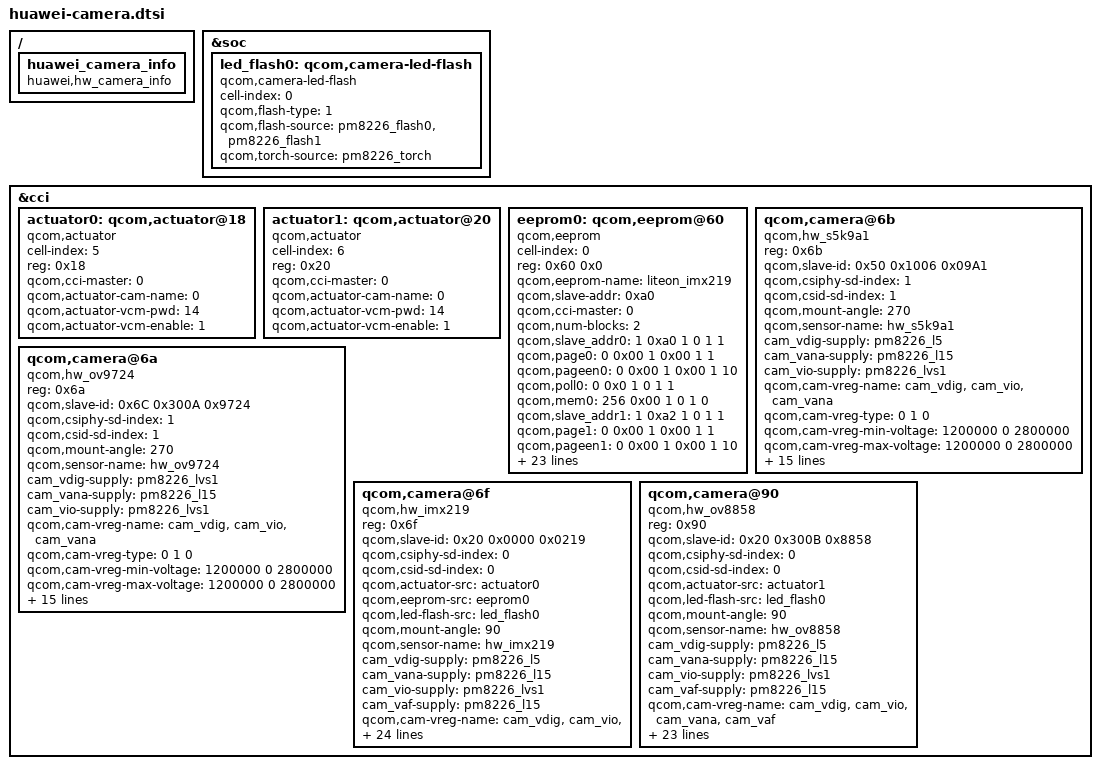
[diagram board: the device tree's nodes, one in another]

 / {
        huawei_camera_info {
                  compatible = "huawei,hw_camera_info";
                  status = "ok";
        };
};

&soc {

	led_flash0: qcom,camera-led-flash {
		cell-index = <0>;
		compatible = "qcom,camera-led-flash";
		qcom,flash-type = <1>;
		qcom,flash-source = <&pm8226_flash0 &pm8226_flash1>;
		qcom,torch-source = <&pm8226_torch>;
	};
};

&cci {
	actuator0: qcom,actuator@18 {
		cell-index = <5>;
		reg = <0x18>;
		compatible = "qcom,actuator";
		qcom,cci-master = <0>;
		qcom,actuator-cam-name = <0>;
		qcom,actuator-vcm-pwd = <14>;
		qcom,actuator-vcm-enable = <1>;
	};
	actuator1: qcom,actuator@20 {
		cell-index = <6>;
		reg = <0x20>;
		compatible = "qcom,actuator";
		qcom,cci-master = <0>;
		qcom,actuator-cam-name = <0>;
		qcom,actuator-vcm-pwd = <14>;
		qcom,actuator-vcm-enable = <1>;
	};
	
	eeprom0: qcom,eeprom@60 {
		cell-index = <0>;
		reg = <0x60 0x0>; //a fake addr for register, mclk src already defined 6-0060.
		qcom,eeprom-name = "liteon_imx219";
		compatible = "qcom,eeprom";
		qcom,slave-addr = <0xa0>;
		qcom,cci-master = <0>;
		qcom,num-blocks = <2>;
		qcom,slave_addr0 = <1 0xa0 1 0 1 1>;
		qcom,page0 = <0 0x00 1 0x00 1 1>;
		qcom,pageen0 = <0 0x00 1 0x00 1 10>;
		qcom,poll0 = <0 0x0 1 0 1 1>;
		qcom,mem0 = <256 0x00 1 0 1 0>;

		qcom,slave_addr1 = <1 0xa2 1 0 1 1>;
		qcom,page1 = <0 0x00 1 0x00 1 1>;
		qcom,pageen1 = <0 0x00 1 0x00 1 10>;
		qcom,poll1 = <0 0x0 1 0 1 1>;
		qcom,mem1 = <40 0x00 1 0 1 0>;

		cam_vdig-supply = <&pm8226_l5>;
		cam_vio-supply = <&pm8226_lvs1>;
		cam_vana-supply = <&pm8226_l15>;
		qcom,cam-vreg-name = "cam_vdig", "cam_vio", "cam_vana";
		qcom,cam-vreg-type = <0 1 0>;
		qcom,cam-vreg-min-voltage = <1200000 0 2800000>;
		qcom,cam-vreg-max-voltage = <1200000 0 2800000>;
		qcom,cam-vreg-op-mode = <200000 0 80000>;
		qcom,gpio-no-mux = <0>;
		gpios = <&msmgpio 26 0>,
			<&msmgpio 37 0>;//reset
		qcom,gpio-reset = <1>;
		qcom,gpio-req-tbl-num = <0 1>;
		qcom,gpio-req-tbl-flags = <1 0>;
		qcom,gpio-req-tbl-label = "CAMIF_MCLK",
				"CAM_RESET";
		qcom,cam-power-seq-type = "sensor_vreg",
				"sensor_vreg", "sensor_gpio",
				"sensor_clk";
		qcom,cam-power-seq-val = "cam_vio", "cam_vana",
				"sensor_gpio_reset",
				"sensor_cam_mclk" ;
		qcom,cam-power-seq-cfg-val = <1 1 1 24000000>;
		qcom,cam-power-seq-delay = <1 1 10 5>;
	};
	
	qcom,camera@6b {
		compatible = "qcom,hw_s5k9a1";
		reg = <0x6b>;
		qcom,slave-id = <0x50 0x1006 0x09A1>;
		qcom,csiphy-sd-index = <1>;
		qcom,csid-sd-index = <1>;
		qcom,mount-angle = <270>;
		qcom,sensor-name = "hw_s5k9a1";
		cam_vdig-supply = <&pm8226_l5>;
		cam_vana-supply = <&pm8226_l15>;
		cam_vio-supply = <&pm8226_lvs1>;
		qcom,cam-vreg-name = "cam_vdig", "cam_vio", "cam_vana";
		qcom,cam-vreg-type = <0 1 0>;
		qcom,cam-vreg-min-voltage = <1200000 0 2800000>;
		qcom,cam-vreg-max-voltage = <1200000 0 2800000>;
		qcom,cam-vreg-op-mode = <200000 0 80000>;
		qcom,gpio-no-mux = <0>;
		gpios = <&msmgpio 26 0>,
				<&msmgpio 28 0>;
		qcom,gpio-reset = <1>;
		qcom,gpio-req-tbl-num = <0 1>;
		qcom,gpio-req-tbl-flags = <1 0>;
		qcom,gpio-req-tbl-label = "CAMIF_MCLK",
				"CAM_RESET";
		qcom,gpio-set-tbl-num = <0 1>;
		qcom,gpio-set-tbl-flags = <1 0>;
		qcom,gpio-set-tbl-delay = <1000 4000>;
		qcom,csi-lane-assign = <0x4320>;
		qcom,csi-lane-mask = <0x3>;
		qcom,sensor-position = <1>;
		qcom,sensor-mode = <1>;
		qcom,cci-master = <0>;
		status = "ok";
	};
	qcom,camera@6a {
		compatible = "qcom,hw_ov9724";
		reg = <0x6a>;
		qcom,slave-id = <0x6C 0x300A 0x9724>;
		qcom,csiphy-sd-index = <1>;
		qcom,csid-sd-index = <1>;
		qcom,mount-angle = <270>;   /* not preset so far */
		qcom,sensor-name = "hw_ov9724";
		cam_vdig-supply = <&pm8226_lvs1>;
		cam_vana-supply = <&pm8226_l15>;
		cam_vio-supply = <&pm8226_lvs1>;
		qcom,cam-vreg-name = "cam_vdig", "cam_vio", "cam_vana";
		qcom,cam-vreg-type = <0 1 0>;
		qcom,cam-vreg-min-voltage = <1200000 0 2800000>;
		qcom,cam-vreg-max-voltage = <1200000 0 2800000>;
		qcom,cam-vreg-op-mode = <200000 0 80000>;
		qcom,gpio-no-mux = <0>;
		gpios = <&msmgpio 26 0>,
				<&msmgpio 28 0>;
		qcom,gpio-reset = <1>;
		qcom,gpio-req-tbl-num = <0 1>;
		qcom,gpio-req-tbl-flags = <1 0>;
		qcom,gpio-req-tbl-label = "CAMIF_MCLK",
				"CAM_RESET";
		qcom,gpio-set-tbl-num = <0 1>;
		qcom,gpio-set-tbl-flags = <1 0>;
		qcom,gpio-set-tbl-delay = <1000 4000>;
		qcom,csi-lane-assign = <0xE4>;
		qcom,csi-lane-mask = <0xF>;
		qcom,sensor-position = <1>;
		qcom,sensor-mode = <1>;
		qcom,cci-master = <0>;
		status = "ok";
	};
	qcom,camera@6f{
		compatible = "qcom,hw_imx219";
		reg = <0x6f>;
		qcom,slave-id = <0x20 0x0000 0x0219>;
		qcom,csiphy-sd-index = <0>;
		qcom,csid-sd-index = <0>;
		qcom,actuator-src = <&actuator0>;
		qcom,eeprom-src = <&eeprom0>;
		qcom,led-flash-src = <&led_flash0>;
		qcom,mount-angle = <90>;
		qcom,sensor-name = "hw_imx219";
		cam_vdig-supply = <&pm8226_l5>;
		cam_vana-supply = <&pm8226_l15>;
		cam_vio-supply = <&pm8226_lvs1>;
		cam_vaf-supply = <&pm8226_l15>;
		qcom,cam-vreg-name = "cam_vdig", "cam_vio",
					"cam_vana", "cam_vaf";
		qcom,cam-vreg-type = <0 1 0 0>;
		qcom,cam-vreg-min-voltage = <1200000 0 2800000 2800000>;
		qcom,cam-vreg-max-voltage = <1200000 0 2800000 2800000>;
		qcom,cam-vreg-op-mode = <200000 0 80000 100000>;
		qcom,gpio-no-mux = <0>;
		gpios = <&msmgpio 26 0>,
			<&msmgpio 36 0>,
			<&msmgpio 37 0>;
		qcom,gpio-reset = <2>;
		qcom,gpio-standby = <1>;
		qcom,gpio-req-tbl-num = <0 1 2>;
		qcom,gpio-req-tbl-flags = <1 0 0>;
		qcom,gpio-req-tbl-label = "CAMIF_MCLK",
			"CAM_STANDBY",
			"CAM_RESET";
		qcom,gpio-set-tbl-num = <2>;
		qcom,gpio-set-tbl-flags = <2>;
		qcom,gpio-set-tbl-delay = <2500>;
		qcom,csi-lane-assign = <0xE4>;
		qcom,csi-lane-mask = <0xF>;
		qcom,sensor-position = <0>;
		qcom,sensor-mode = <0>;
		qcom,sensor-type = <0>;
		qcom,cci-master = <0>;
		status = "ok";
	};
	qcom,camera@90{
		compatible = "qcom,hw_ov8858";
		reg = <0x90>;
		qcom,slave-id = <0x20 0x300B 0x8858>;
		qcom,csiphy-sd-index = <0>;
		qcom,csid-sd-index = <0>;
		qcom,actuator-src = <&actuator1>;
		qcom,led-flash-src = <&led_flash0>;
		qcom,mount-angle = <90>;
		qcom,sensor-name = "hw_ov8858";
		cam_vdig-supply = <&pm8226_l5>;
		cam_vana-supply = <&pm8226_l15>;
		cam_vio-supply = <&pm8226_lvs1>;
		cam_vaf-supply = <&pm8226_l15>;
		qcom,cam-vreg-name = "cam_vdig", "cam_vio",
					"cam_vana", "cam_vaf";
		qcom,cam-vreg-type = <0 1 0 0>;
		qcom,cam-vreg-min-voltage = <1200000 0 2800000 2800000>;
		qcom,cam-vreg-max-voltage = <1200000 0 2800000 2800000>;
		qcom,cam-vreg-op-mode = <200000 0 80000 100000>;
		qcom,gpio-no-mux = <0>;
		gpios = <&msmgpio 26 0>,
			<&msmgpio 36 0>,
			<&msmgpio 37 0>;
		qcom,gpio-reset = <2>;
		qcom,gpio-standby = <1>;
		qcom,gpio-req-tbl-num = <0 1 2>;
		qcom,gpio-req-tbl-flags = <1 0 0>;
		qcom,gpio-req-tbl-label = "CAMIF_MCLK",
			"CAM_STANDBY",
			"CAM_RESET";
		qcom,gpio-set-tbl-num = <2>;
		qcom,gpio-set-tbl-flags = <2>;
		qcom,gpio-set-tbl-delay = <2500>;
		qcom,csi-lane-assign = <0x4320>;
		qcom,csi-lane-mask = <0x1F>;
		qcom,sensor-position = <0>;
		qcom,sensor-mode = <0>;
		qcom,sensor-type = <0>;
		qcom,cci-master = <0>;
		status = "ok";
	};


};

